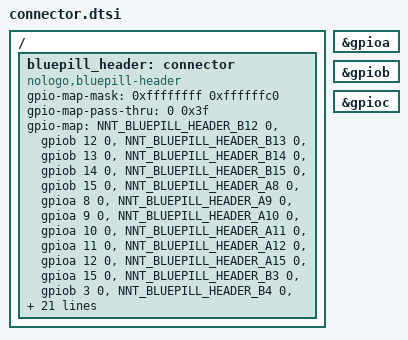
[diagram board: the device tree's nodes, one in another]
/*
 * SPDX-FileCopyrightText: Copyright (c) 2025-2026 TiaC Systems
 * SPDX-License-Identifier: Apache-2.0
 */

#include <zephyr/dt-bindings/gpio/nologo-bluepill-header.h>

/ {
	bluepill_header: connector {
		compatible = "nologo,bluepill-header";
		#gpio-cells = <2>;
		gpio-map-mask = <0xffffffff 0xffffffc0>;
		gpio-map-pass-thru = <0 0x3f>;
		gpio-map = <NNT_BLUEPILL_HEADER_B12 0 &gpiob 12 0>,	/* SPI2 (NSS) */
			   <NNT_BLUEPILL_HEADER_B13 0 &gpiob 13 0>,	/* SPI2 (SCK) */
			   <NNT_BLUEPILL_HEADER_B14 0 &gpiob 14 0>,	/* SPI2 (MISO) */
			   <NNT_BLUEPILL_HEADER_B15 0 &gpiob 15 0>,	/* SPI2 (MOSI) */
			   <NNT_BLUEPILL_HEADER_A8 0 &gpioa 8 0>,	/* GPIO (MCO)*/
			   <NNT_BLUEPILL_HEADER_A9 0 &gpioa 9 0>,	/* USART1 (TX) */
			   <NNT_BLUEPILL_HEADER_A10 0 &gpioa 10 0>,	/* USART1 (RX) */
			   <NNT_BLUEPILL_HEADER_A11 0 &gpioa 11 0>,	/* USBD (DN) */
			   <NNT_BLUEPILL_HEADER_A12 0 &gpioa 12 0>,	/* USBD (DP) */
			   <NNT_BLUEPILL_HEADER_A15 0 &gpioa 15 0>,	/* GPIO */
			   <NNT_BLUEPILL_HEADER_B3 0 &gpiob 3 0>,	/* GPIO */
			   <NNT_BLUEPILL_HEADER_B4 0 &gpiob 4 0>,	/* GPIO */
			   <NNT_BLUEPILL_HEADER_B5 0 &gpiob 5 0>,	/* GPIO */
			   <NNT_BLUEPILL_HEADER_B6 0 &gpiob 6 0>,	/* I2C1 (SCL) */
			   <NNT_BLUEPILL_HEADER_B7 0 &gpiob 7 0>,	/* I2C1 (SDA) */
			   <NNT_BLUEPILL_HEADER_B8 0 &gpiob 8 0>,	/* CAN1 (RX) */
			   <NNT_BLUEPILL_HEADER_B9 0 &gpiob 9 0>,	/* CAN1 (TX) */
			   <NNT_BLUEPILL_HEADER_C13 0 &gpioc 13 0>,	/* GPIO */
			   <NNT_BLUEPILL_HEADER_C14 0 &gpioc 14 0>,	/* GPIO (OSC32 IN) */
			   <NNT_BLUEPILL_HEADER_C15 0 &gpioc 15 0>,	/* GPIO (OSC32 OUT) */
			   <NNT_BLUEPILL_HEADER_A0 0 &gpioa 0 0>,	/* ADC0 (WKUP) */
			   <NNT_BLUEPILL_HEADER_A1 0 &gpioa 1 0>,	/* ADC1 */
			   <NNT_BLUEPILL_HEADER_A2 0 &gpioa 2 0>,	/* ADC2 */
			   <NNT_BLUEPILL_HEADER_A3 0 &gpioa 3 0>,	/* ADC3 */
			   <NNT_BLUEPILL_HEADER_A4 0 &gpioa 4 0>,	/* ADC4 */
			   <NNT_BLUEPILL_HEADER_A5 0 &gpioa 5 0>,	/* ADC5 */
			   <NNT_BLUEPILL_HEADER_A6 0 &gpioa 6 0>,	/* ADC6 */
			   <NNT_BLUEPILL_HEADER_A7 0 &gpioa 7 0>,	/* ADC7 */
			   <NNT_BLUEPILL_HEADER_B0 0 &gpiob 0 0>,	/* ADC8 */
			   <NNT_BLUEPILL_HEADER_B1 0 &gpiob 1 0>,	/* ADC9 */
			   <NNT_BLUEPILL_HEADER_B10 0 &gpiob 10 0>,	/* I2C2 (SCL) */
			   <NNT_BLUEPILL_HEADER_B11 0 &gpiob 11 0>;	/* I2C2 (SDA) */
	};
};

&gpioa {
	status = "okay";
};

&gpiob {
	status = "okay";
};

&gpioc {
	status = "okay";
};
